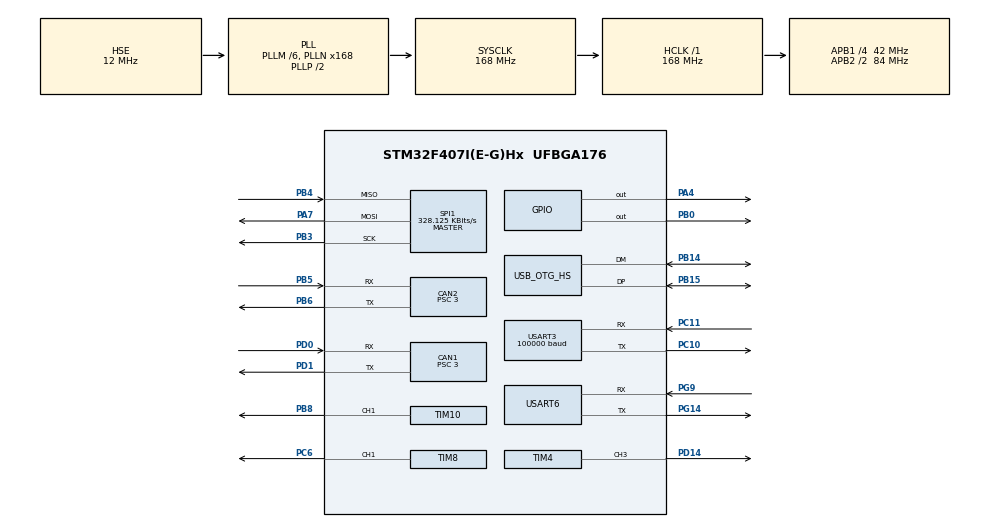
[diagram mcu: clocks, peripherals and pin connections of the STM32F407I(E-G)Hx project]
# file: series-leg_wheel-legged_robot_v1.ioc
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CAN1.ABOM=ENABLE
CAN1.BS1=CAN_BS1_10TQ
CAN1.BS2=CAN_BS2_3TQ
CAN1.CalculateBaudRate=1000000
CAN1.CalculateTimeBit=1000
CAN1.CalculateTimeQuantum=71.42857142857143
CAN1.NART=ENABLE
CAN1.Prescaler=3
CAN1.TXFP=ENABLE
CAN2.ABOM=ENABLE
CAN2.BS1=CAN_BS1_10TQ
CAN2.BS2=CAN_BS2_3TQ
CAN2.CalculateBaudRate=1000000
CAN2.CalculateTimeBit=1000
CAN2.CalculateTimeQuantum=71.42857142857143
CAN2.NART=ENABLE
CAN2.Prescaler=3
CAN2.TXFP=ENABLE
Dma.Request0=USART3_RX
Dma.Request1=USART6_RX
Dma.Request2=USART6_TX
Dma.USART3_RX.0.Direction=DMA_PERIPH_TO_MEMORY
Dma.USART3_RX.0.FIFOMode=DMA_FIFOMODE_DISABLE
Dma.USART3_RX.0.Instance=DMA1_Stream1
Dma.USART3_RX.0.MemDataAlignment=DMA_MDATAALIGN_BYTE
Dma.USART3_RX.0.MemInc=DMA_MINC_ENABLE
Dma.USART3_RX.0.Mode=DMA_NORMAL
Dma.USART3_RX.0.PeriphDataAlignment=DMA_PDATAALIGN_BYTE
Dma.USART3_RX.0.PeriphInc=DMA_PINC_DISABLE
Dma.USART3_RX.0.Priority=DMA_PRIORITY_LOW
Dma.USART6_RX.1.Direction=DMA_PERIPH_TO_MEMORY
Dma.USART6_RX.1.FIFOMode=DMA_FIFOMODE_DISABLE
Dma.USART6_RX.1.Instance=DMA2_Stream1
Dma.USART6_RX.1.MemDataAlignment=DMA_MDATAALIGN_BYTE
Dma.USART6_RX.1.MemInc=DMA_MINC_ENABLE
Dma.USART6_RX.1.Mode=DMA_NORMAL
Dma.USART6_RX.1.PeriphDataAlignment=DMA_PDATAALIGN_BYTE
Dma.USART6_RX.1.PeriphInc=DMA_PINC_DISABLE
Dma.USART6_RX.1.Priority=DMA_PRIORITY_LOW
Dma.USART6_TX.2.Direction=DMA_MEMORY_TO_PERIPH
Dma.USART6_TX.2.FIFOMode=DMA_FIFOMODE_DISABLE
Dma.USART6_TX.2.Instance=DMA2_Stream6
Dma.USART6_TX.2.MemDataAlignment=DMA_MDATAALIGN_BYTE
Dma.USART6_TX.2.MemInc=DMA_MINC_ENABLE
Dma.USART6_TX.2.Mode=DMA_NORMAL
Dma.USART6_TX.2.PeriphDataAlignment=DMA_PDATAALIGN_BYTE
Dma.USART6_TX.2.PeriphInc=DMA_PINC_DISABLE
Dma.USART6_TX.2.Priority=DMA_PRIORITY_LOW
FREERTOS.Tasks01=defaultTask,0,128,StartDefaultTask,Default,NULL,Dynamic,NULL,NULL;Task_1ms,-3,128,task_1ms,As weak,NULL,Dynamic,NULL,NULL;Task_100ms,3,128,task_100ms,As weak,NULL,Dynamic,NULL,NULL;IMU_Task,-3,128,IMU_task,As weak,NULL,Dynamic,NULL,NULL
Mcu.Family=STM32F4
Mcu.Name=STM32F407I(E-G)Hx
Mcu.Package=UFBGA176
NVIC.CAN1_RX0_IRQn=true\:5\:0\:false\:false\:true\:true\:true\:true\:true
NVIC.CAN2_RX0_IRQn=true\:5\:0\:false\:false\:true\:true\:true\:true\:true
NVIC.DMA1_Stream1_IRQn=true\:5\:0\:false\:false\:true\:true\:false\:true\:true
NVIC.DMA2_Stream1_IRQn=true\:5\:0\:false\:false\:true\:true\:false\:true\:true
NVIC.DMA2_Stream6_IRQn=true\:5\:0\:false\:false\:true\:true\:false\:true\:true
NVIC.OTG_HS_IRQn=true\:5\:0\:false\:false\:true\:true\:false\:true\:true
NVIC.PriorityGroup=NVIC_PRIORITYGROUP_4
NVIC.TIM8_TRG_COM_TIM14_IRQn=true\:15\:0\:false\:false\:true\:false\:false\:true\:true
NVIC.TimeBase=TIM8_TRG_COM_TIM14_IRQn
NVIC.TimeBaseIP=TIM14
NVIC.USART3_IRQn=true\:5\:0\:false\:false\:true\:true\:true\:true\:true
NVIC.USART6_IRQn=true\:5\:0\:false\:false\:true\:true\:true\:true\:true
PA13.Mode=Serial_Wire
PA13.Signal=SYS_JTMS-SWDIO
PA14.Mode=Serial_Wire
PA14.Signal=SYS_JTCK-SWCLK
PA4.Signal=GPIO_Output
PA7.Mode=Full_Duplex_Master
PA7.Signal=SPI1_MOSI
PB0.Signal=GPIO_Output
PB14.Mode=Device_Only_FS
PB14.Signal=USB_OTG_HS_DM
PB15.Mode=Device_Only_FS
PB15.Signal=USB_OTG_HS_DP
PB3.Mode=Full_Duplex_Master
PB3.Signal=SPI1_SCK
PB4.Mode=Full_Duplex_Master
PB4.Signal=SPI1_MISO
PB5.Mode=CAN_Activate
PB5.Signal=CAN2_RX
PB6.Mode=CAN_Activate
PB6.Signal=CAN2_TX
PB8.Signal=S_TIM10_CH1
PC10.Mode=Asynchronous
PC10.Signal=USART3_TX
PC11.Mode=Asynchronous
PC11.Signal=USART3_RX
PC6.Signal=S_TIM8_CH1
PD0.Mode=CAN_Activate
PD0.Signal=CAN1_RX
PD1.Mode=CAN_Activate
PD1.Signal=CAN1_TX
PD14.Signal=S_TIM4_CH3
PG14.Mode=Asynchronous
PG14.Signal=USART6_TX
PG9.Mode=Asynchronous
PG9.Signal=USART6_RX
PH0-OSC_IN.Mode=HSE-External-Oscillator
PH0-OSC_IN.Signal=RCC_OSC_IN
PH1-OSC_OUT.Mode=HSE-External-Oscillator
PH1-OSC_OUT.Signal=RCC_OSC_OUT
ProjectManager.HeapSize=0x200
ProjectManager.StackSize=0x400
ProjectManager.TargetToolchain=CMake
RCC.48MHZClocksFreq_Value=48000000
RCC.AHBFreq_Value=168000000
RCC.APB1CLKDivider=RCC_HCLK_DIV4
RCC.APB1Freq_Value=42000000
RCC.APB1TimFreq_Value=84000000
RCC.APB2CLKDivider=RCC_HCLK_DIV2
RCC.APB2Freq_Value=84000000
RCC.APB2TimFreq_Value=168000000
RCC.CortexFreq_Value=168000000
RCC.HCLKFreq_Value=168000000
RCC.HSE_VALUE=12000000
RCC.HSI_VALUE=16000000
RCC.LSE_VALUE=32768
RCC.PLLM=6
RCC.PLLN=168
RCC.PLLQ=7
RCC.SYSCLKFreq_VALUE=168000000
RCC.SYSCLKSource=RCC_SYSCLKSOURCE_PLLCLK
RCC.VCOOutputFreq_Value=336000000
SH.S_TIM10_CH1.0=TIM10_CH1,PWM Generation1 CH1
SH.S_TIM4_CH3.0=TIM4_CH3,PWM Generation3 CH3
SH.S_TIM8_CH1.0=TIM8_CH1,Output Compare1 CH1
SPI1.BaudRatePrescaler=SPI_BAUDRATEPRESCALER_256
SPI1.CLKPhase=SPI_PHASE_2EDGE
SPI1.CLKPolarity=SPI_POLARITY_HIGH
SPI1.CalculateBaudRate=328.125 KBits/s
SPI1.Direction=SPI_DIRECTION_2LINES
SPI1.Mode=SPI_MODE_MASTER
SPI1.VirtualType=VM_MASTER
TIM10.Channel=TIM_CHANNEL_1
TIM10.Period=10000-1
TIM10.Prescaler=24-1
TIM4.AutoReloadPreload=TIM_AUTORELOAD_PRELOAD_ENABLE
TIM4.Channel-PWM\ Generation3\ CH3=TIM_CHANNEL_3
TIM4.Period=65535
TIM4.Prescaler=167
TIM8.Channel-Output\ Compare1\ CH1=TIM_CHANNEL_1
USART3.BaudRate=100000
USART3.Parity=PARITY_EVEN
USART3.StopBits=STOPBITS_2
USART3.VirtualMode=VM_ASYNC
USART3.WordLength=WORDLENGTH_9B
USART6.VirtualMode=VM_ASYNC
USB_DEVICE.CLASS_NAME_HS=CDC
USB_DEVICE.VirtualMode-CDC_HS=Cdc
USB_DEVICE.VirtualModeHS=Cdc_HS
USB_OTG_HS.VirtualMode-Device_Only_FS=Device_Only_FS
VP_FREERTOS_VS_CMSIS_V1.Mode=CMSIS_V1
VP_SYS_VS_tim14.Mode=TIM14
VP_TIM10_VS_ClockSourceINT.Mode=Enable_Timer
VP_USB_DEVICE_VS_USB_DEVICE_CDC_HS.Mode=CDC_HS
board=custom

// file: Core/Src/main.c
/* USER CODE BEGIN Header */
/**
  ******************************************************************************
  * @file           : main.c
  * @brief          : Main program body
  ******************************************************************************
  * @attention
  *
  * Copyright (c) 2025 STMicroelectronics.
  * All rights reserved.
  *
  * This software is licensed under terms that can be found in the LICENSE file
  * in the root directory of this software component.
  * If no LICENSE file comes with this software, it is provided AS-IS.
  *
  ******************************************************************************
  */
/* USER CODE END Header */
#include "main.h"
#include "cmsis_os.h"
#include "can.h"
#include "dma.h"
#include "spi.h"
#include "tim.h"
#include "usart.h"
#include "usb_device.h"
#include "gpio.h"

/* USER CODE BEGIN Includes */
#include "fliter.h"
#include "Init.h"
#include "buzzer.h"
#include "remoter.h"
#include "remoter.h"
/* USER CODE END Includes */

void SystemClock_Config(void);
void MX_FREERTOS_Init(void);

/* USER CODE BEGIN 0 */
uint8_t up_board_data[128] = {0};
/* USER CODE END 0 */

int main(void)
{

  /* MCU Configuration--------------------------------------------------------*/

  /* Reset of all peripherals, Initializes the Flash interface and the Systick. */
   HAL_Init();

  /* Configure the system clock */
  SystemClock_Config();

  /* Initialize all configured peripherals */
  MX_GPIO_Init();
  MX_DMA_Init();
  MX_CAN1_Init();
  MX_SPI1_Init();
  MX_TIM8_Init();
  MX_USART3_UART_Init();
  MX_TIM10_Init();
  MX_CAN2_Init();
  MX_TIM4_Init();
  MX_USART6_UART_Init();
  /* USER CODE BEGIN 2 */

  Buzzer_init();
  can_filter_init();
  car_init ();
	Remoter_Init();
  HAL_UARTEx_ReceiveToIdle_DMA(&huart6,up_board_data,128);

  /* USER CODE END 2 */

  /* Call init function for freertos objects (in cmsis_os2.c) */
  MX_FREERTOS_Init();

  /* Start scheduler */
  osKernelStart();

  /* We should never get here as control is now taken by the scheduler */

  /* Infinite loop */
  while (1)
  {

  }
}

void SystemClock_Config(void)
{
  RCC_OscInitTypeDef RCC_OscInitStruct = {0};
  RCC_ClkInitTypeDef RCC_ClkInitStruct = {0};

  /** Configure the main internal regulator output voltage
  */
  __HAL_RCC_PWR_CLK_ENABLE();
  __HAL_PWR_VOLTAGESCALING_CONFIG(PWR_REGULATOR_VOLTAGE_SCALE1);

  /** Initializes the RCC Oscillators according to the specified parameters
  * in the RCC_OscInitTypeDef structure.
  */
  RCC_OscInitStruct.OscillatorType = RCC_OSCILLATORTYPE_HSE;
  RCC_OscInitStruct.HSEState = RCC_HSE_ON;
  RCC_OscInitStruct.PLL.PLLState = RCC_PLL_ON;
  RCC_OscInitStruct.PLL.PLLSource = RCC_PLLSOURCE_HSE;
  RCC_OscInitStruct.PLL.PLLM = 6;
  RCC_OscInitStruct.PLL.PLLN = 168;
  RCC_OscInitStruct.PLL.PLLP = RCC_PLLP_DIV2;
  RCC_OscInitStruct.PLL.PLLQ = 7;
  if (HAL_RCC_OscConfig(&RCC_OscInitStruct) != HAL_OK)
  {
    Error_Handler();
  }

  /** Initializes the CPU, AHB and APB buses clocks
  */
  RCC_ClkInitStruct.ClockType = RCC_CLOCKTYPE_HCLK|RCC_CLOCKTYPE_SYSCLK
                              |RCC_CLOCKTYPE_PCLK1|RCC_CLOCKTYPE_PCLK2;
  RCC_ClkInitStruct.SYSCLKSource = RCC_SYSCLKSOURCE_PLLCLK;
  RCC_ClkInitStruct.AHBCLKDivider = RCC_SYSCLK_DIV1;
  RCC_ClkInitStruct.APB1CLKDivider = RCC_HCLK_DIV4;
  RCC_ClkInitStruct.APB2CLKDivider = RCC_HCLK_DIV2;

  if (HAL_RCC_ClockConfig(&RCC_ClkInitStruct, FLASH_LATENCY_5) != HAL_OK)
  {
    Error_Handler();
  }
}

void HAL_TIM_PeriodElapsedCallback(TIM_HandleTypeDef *htim)
{
  if (htim->Instance == TIM14)
  {
    HAL_IncTick();
  }
}

void Error_Handler(void)
{
  __disable_irq();
  while (1)
  {
  }
}

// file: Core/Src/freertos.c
/* USER CODE BEGIN Header */
/**
  ******************************************************************************
  * File Name          : freertos.c
  * Description        : Code for freertos applications
  ******************************************************************************
  * @attention
  *
  * Copyright (c) 2025 STMicroelectronics.
  * All rights reserved.
  *
  * This software is licensed under terms that can be found in the LICENSE file
  * in the root directory of this software component.
  * If no LICENSE file comes with this software, it is provided AS-IS.
  *
  ******************************************************************************
  */
/* USER CODE END Header */

#include "FreeRTOS.h"
#include "task.h"
#include "main.h"
#include "cmsis_os.h"

osThreadId defaultTaskHandle;
osThreadId Task_1msHandle;
osThreadId Task_100msHandle;
osThreadId IMU_TaskHandle;

void StartDefaultTask(void const * argument);
void task_1ms(void const * argument);
void task_100ms(void const * argument);
void IMU_task(void const * argument);

extern void MX_USB_DEVICE_Init(void);
void MX_FREERTOS_Init(void); /* (MISRA C 2004 rule 8.1) */

/* GetIdleTaskMemory prototype (linked to static allocation support) */
void vApplicationGetIdleTaskMemory( StaticTask_t **ppxIdleTaskTCBBuffer, StackType_t **ppxIdleTaskStackBuffer, uint32_t *pulIdleTaskStackSize );

/* USER CODE BEGIN GET_IDLE_TASK_MEMORY */
static StaticTask_t xIdleTaskTCBBuffer;
static StackType_t xIdleStack[configMINIMAL_STACK_SIZE];

void vApplicationGetIdleTaskMemory( StaticTask_t **ppxIdleTaskTCBBuffer, StackType_t **ppxIdleTaskStackBuffer, uint32_t *pulIdleTaskStackSize )
{
  *ppxIdleTaskTCBBuffer = &xIdleTaskTCBBuffer;
  *ppxIdleTaskStackBuffer = &xIdleStack[0];
  *pulIdleTaskStackSize = configMINIMAL_STACK_SIZE;
  /* place for user code */
}
/* USER CODE END GET_IDLE_TASK_MEMORY */

void MX_FREERTOS_Init(void) {

  /* Create the thread(s) */
  /* definition and creation of defaultTask */
  osThreadDef(defaultTask, StartDefaultTask, osPriorityNormal, 0, 128);
  defaultTaskHandle = osThreadCreate(osThread(defaultTask), NULL);

  /* definition and creation of Task_1ms */
  osThreadDef(Task_1ms, task_1ms, osPriorityIdle, 0, 128);
  Task_1msHandle = osThreadCreate(osThread(Task_1ms), NULL);

  /* definition and creation of Task_100ms */
  osThreadDef(Task_100ms, task_100ms, osPriorityRealtime, 0, 128);
  Task_100msHandle = osThreadCreate(osThread(Task_100ms), NULL);

  /* definition and creation of IMU_Task */
  osThreadDef(IMU_Task, IMU_task, osPriorityIdle, 0, 128);
  IMU_TaskHandle = osThreadCreate(osThread(IMU_Task), NULL);

}

void StartDefaultTask(void const * argument)
{
  /* init code for USB_DEVICE */
  MX_USB_DEVICE_Init();
  for(;;)
  {
    osDelay(1);
  }
}

__weak void task_1ms(void const * argument)
{
  for(;;)
  {
    osDelay(1);
  }
}

__weak void task_100ms(void const * argument)
{
  /* USER CODE BEGIN task_100ms */
  /* Infinite loop */
  for(;;)
  {
    osDelay(100);
  }
  /* USER CODE END task_100ms */
}

__weak void IMU_task(void const * argument)
{
  for(;;)
  {
    osDelay(1);
  }
}
